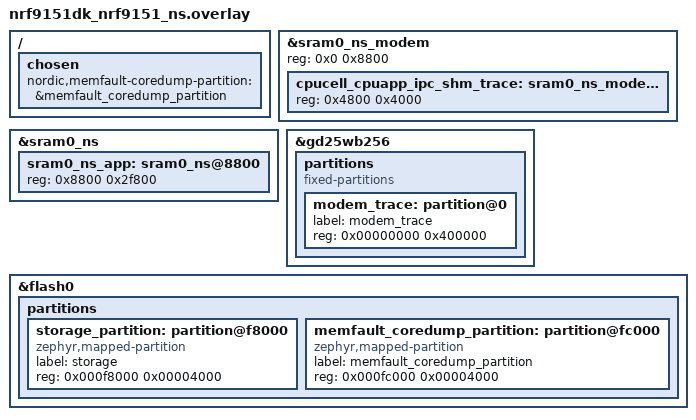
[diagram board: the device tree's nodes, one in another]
/*
 * Copyright (c) 2025 Nordic Semiconductor ASA
 *
 * SPDX-License-Identifier: LicenseRef-Nordic-5-Clause
 */

#include <samples/cellular/nrf91_no_bootloader_partitions.dtsi>

#include <samples/cellular/nrf91_sram_partitions.dtsi>

/* Increase modem (shared) memory. */
&sram0_ns_modem {
	reg = <0x0 0x8800>;
	ranges = <0x0 0x0 0x8800>;

	cpucell_cpuapp_ipc_shm_trace: sram0_ns_modem@4800 {
		/* Modem trace memory */
		reg = <0x4800 0x4000>;
	};
};

/* Delete Non-Secure application memory so we can move and shrink it. */
/delete-node/ &sram0_ns_app;

&sram0_ns {
	sram0_ns_app: sram0_ns@8800 {
		/* Redefine smaller Non-Secure application memory. */
		reg = <0x8800 0x2f800>;
	};
};

&gd25wb256 {
	status = "okay";

	partitions {
		compatible = "fixed-partitions";
		#address-cells = <1>;
		#size-cells = <1>;

		modem_trace: partition@0 {
			label = "modem_trace";
			reg = <0x00000000 0x400000>;
		};
	};
};

/* The internal-flash coredump backend (CONFIG_MEMFAULT_NCS_INTERNAL_FLASH_BACKED_COREDUMP)
 * memory-maps the coredump partition and reads it with memcpy(), so it must live in
 * internal flash (not on the external gd25wb256). Carve it out of the storage region.
 */
/delete-node/ &storage_partition;

&flash0 {
	partitions {
		storage_partition: partition@f8000 {
			compatible = "zephyr,mapped-partition";
			label = "storage";
			reg = <0x000f8000 0x00004000>;
		};

		memfault_coredump_partition: partition@fc000 {
			compatible = "zephyr,mapped-partition";
			label = "memfault_coredump_partition";
			reg = <0x000fc000 0x00004000>;
		};
	};
};

/ {
	chosen {
		nordic,memfault-coredump-partition = &memfault_coredump_partition;
	};
};
